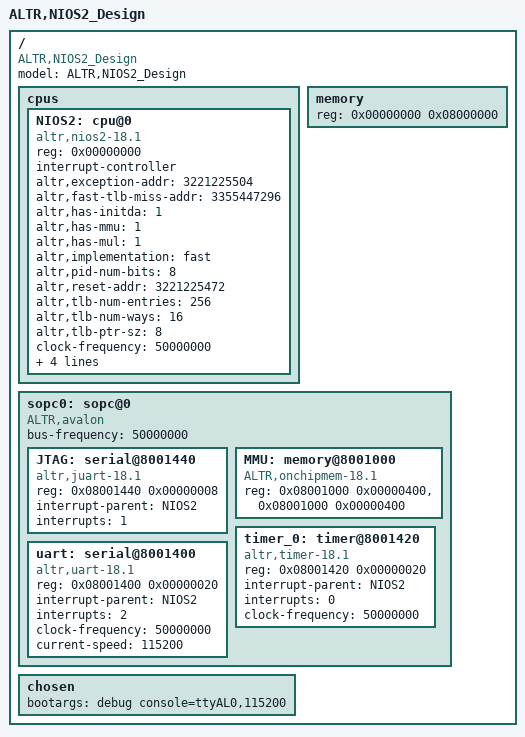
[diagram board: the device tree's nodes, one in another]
/*
 * This devicetree is generated by sopc2dts version unknown on Sun Jan 27 18:39:36 BRST 2019
 * Sopc2dts is written by Walter Goossens <waltergoossens@home.nl>
 * in cooperation with the nios2 community <nios2-dev@lists.rocketboards.org>
 */
/dts-v1/;

/ {
	model = "ALTR,NIOS2_Design";
	compatible = "ALTR,NIOS2_Design";
	#address-cells = <1>;
	#size-cells = <1>;

	cpus {
		#address-cells = <1>;
		#size-cells = <0>;

		NIOS2: cpu@0 {
			device_type = "cpu";
			compatible = "altr,nios2-18.1", "altr,nios2-1.1";
			reg = <0x00000000>;
			interrupt-controller;
			#interrupt-cells = <1>;
			altr,exception-addr = <3221225504>;	/* embeddedsw.dts.params.altr,exception-addr type NUMBER */
			altr,fast-tlb-miss-addr = <3355447296>;	/* embeddedsw.dts.params.altr,fast-tlb-miss-addr type NUMBER */
			altr,has-initda = <1>;	/* embeddedsw.dts.params.altr,has-initda type NUMBER */
			altr,has-mmu = <1>;	/* embeddedsw.dts.params.altr,has-mmu type NUMBER */
			altr,has-mul = <1>;	/* embeddedsw.dts.params.altr,has-mul type NUMBER */
			altr,implementation = "fast";	/* embeddedsw.dts.params.altr,implementation type STRING */
			altr,pid-num-bits = <8>;	/* embeddedsw.dts.params.altr,pid-num-bits type NUMBER */
			altr,reset-addr = <3221225472>;	/* embeddedsw.dts.params.altr,reset-addr type NUMBER */
			altr,tlb-num-entries = <256>;	/* embeddedsw.dts.params.altr,tlb-num-entries type NUMBER */
			altr,tlb-num-ways = <16>;	/* embeddedsw.dts.params.altr,tlb-num-ways type NUMBER */
			altr,tlb-ptr-sz = <8>;	/* embeddedsw.dts.params.altr,tlb-ptr-sz type NUMBER */
			clock-frequency = <50000000>;	/* embeddedsw.dts.params.clock-frequency type NUMBER */
			dcache-line-size = <32>;	/* embeddedsw.dts.params.dcache-line-size type NUMBER */
			dcache-size = <2048>;	/* embeddedsw.dts.params.dcache-size type NUMBER */
			icache-line-size = <32>;	/* embeddedsw.dts.params.icache-line-size type NUMBER */
			icache-size = <4096>;	/* embeddedsw.dts.params.icache-size type NUMBER */
		}; //end cpu@0 (NIOS2)
	}; //end cpus

	memory {
		device_type = "memory";
		reg = <0x00000000 0x08000000>;
	}; //end memory

	sopc0: sopc@0 {
		device_type = "soc";
		ranges;
		#address-cells = <1>;
		#size-cells = <1>;
		compatible = "ALTR,avalon", "simple-bus";
		bus-frequency = <50000000>;

		JTAG: serial@8001440 {
			compatible = "altr,juart-18.1", "altr,juart-1.0";
			reg = <0x08001440 0x00000008>;
			interrupt-parent = <&NIOS2>;
			interrupts = <1>;
		}; //end serial@8001440 (JTAG)

		MMU: memory@8001000 {
			device_type = "memory";
			compatible = "ALTR,onchipmem-18.1";
			reg = <0x08001000 0x00000400>,
				<0x08001000 0x00000400>;
			reg-names = "s1", "s2";
		}; //end memory@8001000 (MMU)

		timer_0: timer@8001420 {
			compatible = "altr,timer-18.1", "altr,timer-1.0";
			reg = <0x08001420 0x00000020>;
			interrupt-parent = <&NIOS2>;
			interrupts = <0>;
			clock-frequency = <50000000>;	/* embeddedsw.dts.params.clock-frequency type NUMBER */
		}; //end timer@8001420 (timer_0)

		uart: serial@8001400 {
			compatible = "altr,uart-18.1", "altr,uart-1.0";
			reg = <0x08001400 0x00000020>;
			interrupt-parent = <&NIOS2>;
			interrupts = <2>;
			clock-frequency = <50000000>;	/* embeddedsw.dts.params.clock-frequency type NUMBER */
			current-speed = <115200>;	/* embeddedsw.dts.params.current-speed type NUMBER */
		}; //end serial@8001400 (uart)
	}; //end sopc@0 (sopc0)

	chosen {
		bootargs = "debug console=ttyAL0,115200";
	}; //end chosen
}; //end /
